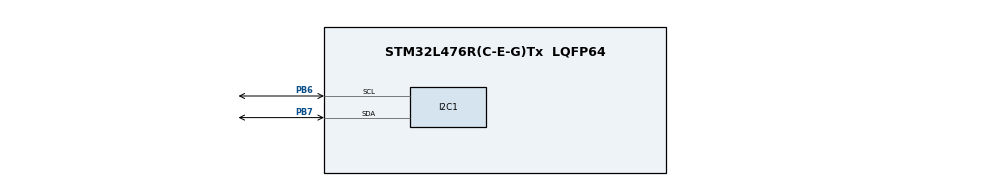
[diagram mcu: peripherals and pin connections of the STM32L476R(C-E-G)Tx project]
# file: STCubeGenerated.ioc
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Mcu.Family=STM32L4
Mcu.Name=STM32L476R(C-E-G)Tx
Mcu.Package=LQFP64
NVIC.PriorityGroup=NVIC_PRIORITYGROUP_4
PA13\ (JTMS-SWDIO).Mode=Serial_Wire
PA13\ (JTMS-SWDIO).Signal=SYS_JTMS-SWDIO
PA14\ (JTCK-SWCLK).Mode=Serial_Wire
PA14\ (JTCK-SWCLK).Signal=SYS_JTCK-SWCLK
PB6.Mode=I2C
PB6.Signal=I2C1_SCL
PB7.Mode=I2C
PB7.Signal=I2C1_SDA
ProjectManager.HeapSize=0x200
ProjectManager.StackSize=0x400
ProjectManager.TargetToolchain=Makefile
RCC.HSE_VALUE=8000000
RCC.HSI_VALUE=16000000
RCC.LSE_VALUE=32768
RCC.MSI_VALUE=4000000
RCC.VCOOutputFreq_Value=32000000
board=STCubeGenerated

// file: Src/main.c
/**
  ******************************************************************************
  * File Name          : main.c
  * Description        : Main program body
  ******************************************************************************
  ** This notice applies to any and all portions of this file
  * that are not between comment pairs USER CODE BEGIN and
  * USER CODE END. Other portions of this file, whether
  * inserted by the user or by software development tools
  * are owned by their respective copyright owners.
  *
  * COPYRIGHT(c) 2018 STMicroelectronics
  *
  * Redistribution and use in source and binary forms, with or without modification,
  * are permitted provided that the following conditions are met:
  *   1. Redistributions of source code must retain the above copyright notice,
  *      this list of conditions and the following disclaimer.
  *   2. Redistributions in binary form must reproduce the above copyright notice,
  *      this list of conditions and the following disclaimer in the documentation
  *      and/or other materials provided with the distribution.
  *   3. Neither the name of STMicroelectronics nor the names of its contributors
  *      may be used to endorse or promote products derived from this software
  *      without specific prior written permission.
  *
  * THIS SOFTWARE IS PROVIDED BY THE COPYRIGHT HOLDERS AND CONTRIBUTORS "AS IS"
  * AND ANY EXPRESS OR IMPLIED WARRANTIES, INCLUDING, BUT NOT LIMITED TO, THE
  * IMPLIED WARRANTIES OF MERCHANTABILITY AND FITNESS FOR A PARTICULAR PURPOSE ARE
  * DISCLAIMED. IN NO EVENT SHALL THE COPYRIGHT HOLDER OR CONTRIBUTORS BE LIABLE
  * FOR ANY DIRECT, INDIRECT, INCIDENTAL, SPECIAL, EXEMPLARY, OR CONSEQUENTIAL
  * DAMAGES (INCLUDING, BUT NOT LIMITED TO, PROCUREMENT OF SUBSTITUTE GOODS OR
  * SERVICES; LOSS OF USE, DATA, OR PROFITS; OR BUSINESS INTERRUPTION) HOWEVER
  * CAUSED AND ON ANY THEORY OF LIABILITY, WHETHER IN CONTRACT, STRICT LIABILITY,
  * OR TORT (INCLUDING NEGLIGENCE OR OTHERWISE) ARISING IN ANY WAY OUT OF THE USE
  * OF THIS SOFTWARE, EVEN IF ADVISED OF THE POSSIBILITY OF SUCH DAMAGE.
  *
  ******************************************************************************
  */

#include "main.h"
#include "stm32l4xx_hal.h"

/* USER CODE BEGIN Includes */
#include "C:\Users\Lex-alviur\Desktop\max_micro\MAX30101_new.h"
/* USER CODE END Includes */

I2C_HandleTypeDef hi2c1;
uint8_t errorCode = 0;
/* USER CODE BEGIN PV */
/* Private variables ---------------------------------------------------------*/

/* USER CODE END PV */

void SystemClock_Config(void);
static void MX_GPIO_Init(void);
static void MX_I2C1_Init(void);

/* USER CODE BEGIN PFP */
/* Private function prototypes -----------------------------------------------*/

/* USER CODE END PFP */

int main(void)
{

  /* MCU Configuration----------------------------------------------------------*/

  /* Reset of all peripherals, Initializes the Flash interface and the Systick. */
  HAL_Init();

  /* Configure the system clock */
  SystemClock_Config();

  /* Initialize all configured peripherals */
  MX_GPIO_Init();
  MX_I2C1_Init();

  /* USER CODE BEGIN 2 */
	errorCode = max30101_init();
	uint32_t fifo_data;
  /* USER CODE END 2 */

  /* Infinite loop */
  while (1)
  {

  /* USER CODE BEGIN 3 */
		fifo_data = max30101_sample_fetch();

  }
  /* USER CODE END 3 */

}

/** System Clock Configuration
*/
void SystemClock_Config(void)
{

  RCC_OscInitTypeDef RCC_OscInitStruct;
  RCC_ClkInitTypeDef RCC_ClkInitStruct;
  RCC_PeriphCLKInitTypeDef PeriphClkInit;

    /**Initializes the CPU, AHB and APB busses clocks
    */
  RCC_OscInitStruct.OscillatorType = RCC_OSCILLATORTYPE_MSI;
  RCC_OscInitStruct.MSIState = RCC_MSI_ON;
  RCC_OscInitStruct.MSICalibrationValue = 0;
  RCC_OscInitStruct.MSIClockRange = RCC_MSIRANGE_6;
  RCC_OscInitStruct.PLL.PLLState = RCC_PLL_NONE;
  if (HAL_RCC_OscConfig(&RCC_OscInitStruct) != HAL_OK)
  {
    _Error_Handler(__FILE__, __LINE__);
  }

    /**Initializes the CPU, AHB and APB busses clocks
    */
  RCC_ClkInitStruct.ClockType = RCC_CLOCKTYPE_HCLK|RCC_CLOCKTYPE_SYSCLK
                              |RCC_CLOCKTYPE_PCLK1|RCC_CLOCKTYPE_PCLK2;
  RCC_ClkInitStruct.SYSCLKSource = RCC_SYSCLKSOURCE_MSI;
  RCC_ClkInitStruct.AHBCLKDivider = RCC_SYSCLK_DIV1;
  RCC_ClkInitStruct.APB1CLKDivider = RCC_HCLK_DIV1;
  RCC_ClkInitStruct.APB2CLKDivider = RCC_HCLK_DIV1;

  if (HAL_RCC_ClockConfig(&RCC_ClkInitStruct, FLASH_LATENCY_0) != HAL_OK)
  {
    _Error_Handler(__FILE__, __LINE__);
  }

  PeriphClkInit.PeriphClockSelection = RCC_PERIPHCLK_I2C1;
  PeriphClkInit.I2c1ClockSelection = RCC_I2C1CLKSOURCE_PCLK1;
  if (HAL_RCCEx_PeriphCLKConfig(&PeriphClkInit) != HAL_OK)
  {
    _Error_Handler(__FILE__, __LINE__);
  }

    /**Configure the main internal regulator output voltage
    */
  if (HAL_PWREx_ControlVoltageScaling(PWR_REGULATOR_VOLTAGE_SCALE1) != HAL_OK)
  {
    _Error_Handler(__FILE__, __LINE__);
  }

    /**Configure the Systick interrupt time
    */
  HAL_SYSTICK_Config(HAL_RCC_GetHCLKFreq()/1000);

    /**Configure the Systick
    */
  HAL_SYSTICK_CLKSourceConfig(SYSTICK_CLKSOURCE_HCLK);

  /* SysTick_IRQn interrupt configuration */
  HAL_NVIC_SetPriority(SysTick_IRQn, 0, 0);
}

/* I2C1 init function */
static void MX_I2C1_Init(void)
{

  hi2c1.Instance = I2C1;
  hi2c1.Init.Timing = 0x00000E14;
  hi2c1.Init.OwnAddress1 = 0;
  hi2c1.Init.AddressingMode = I2C_ADDRESSINGMODE_7BIT;
  hi2c1.Init.DualAddressMode = I2C_DUALADDRESS_DISABLE;
  hi2c1.Init.OwnAddress2 = 0;
  hi2c1.Init.OwnAddress2Masks = I2C_OA2_NOMASK;
  hi2c1.Init.GeneralCallMode = I2C_GENERALCALL_DISABLE;
  hi2c1.Init.NoStretchMode = I2C_NOSTRETCH_DISABLE;
  if (HAL_I2C_Init(&hi2c1) != HAL_OK)
  {
    _Error_Handler(__FILE__, __LINE__);
  }

    /**Configure Analogue filter
    */
  if (HAL_I2CEx_ConfigAnalogFilter(&hi2c1, I2C_ANALOGFILTER_ENABLE) != HAL_OK)
  {
    _Error_Handler(__FILE__, __LINE__);
  }

    /**Configure Digital filter
    */
  if (HAL_I2CEx_ConfigDigitalFilter(&hi2c1, 0) != HAL_OK)
  {
    _Error_Handler(__FILE__, __LINE__);
  }

}

/** Configure pins as
        * Analog
        * Input
        * Output
        * EVENT_OUT
        * EXTI
*/
static void MX_GPIO_Init(void)
{

  /* GPIO Ports Clock Enable */
  __HAL_RCC_GPIOA_CLK_ENABLE();
  __HAL_RCC_GPIOB_CLK_ENABLE();

}

void _Error_Handler(char * file, int line)
{
  while(1)
  {
  }
}

/************************ (C) COPYRIGHT STMicroelectronics *****END OF FILE****/
